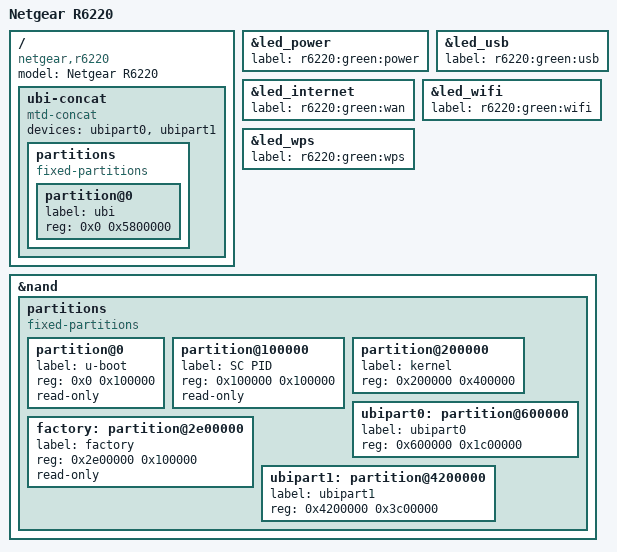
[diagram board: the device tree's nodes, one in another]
// SPDX-License-Identifier: GPL-2.0
/dts-v1/;

#include "mt7621_netgear_sercomm_ayx.dtsi"

/ {
	compatible = "netgear,r6220", "mediatek,mt7621-soc";
	model = "Netgear R6220";
	ubi-concat {
		compatible = "mtd-concat";
		devices = <&ubipart0 &ubipart1>;

		partitions {
			compatible = "fixed-partitions";
			#address-cells = <1>;
			#size-cells = <1>;

			partition@0 {
				label = "ubi";
				reg = <0x0 0x5800000>;
			};
		};
	};
};

&led_power {
	label = "r6220:green:power";
};

&led_usb {
	label = "r6220:green:usb";
};

&led_internet {
	label = "r6220:green:wan";
};

&led_wifi {
	label = "r6220:green:wifi";
};

&led_wps {
	label = "r6220:green:wps";
};

&nand {
	status = "okay";

	partitions {
		compatible = "fixed-partitions";
		#address-cells = <1>;
		#size-cells = <1>;

		partition@0 {
			label = "u-boot";
			reg = <0x0 0x100000>;
			read-only;
		};

		partition@100000 {
			label = "SC PID";
			reg = <0x100000 0x100000>;
			read-only;
		};

		partition@200000 {
			label = "kernel";
			reg = <0x200000 0x400000>;
		};

		ubipart0: partition@600000 {
			label = "ubipart0";
			reg = <0x600000 0x1c00000>;
		};

		factory: partition@2e00000 {
			label = "factory";
			reg = <0x2e00000 0x100000>;
			read-only;
		};

		ubipart1: partition@4200000 {
			label = "ubipart1";
			reg = <0x4200000 0x3c00000>;
		};
	};
};
